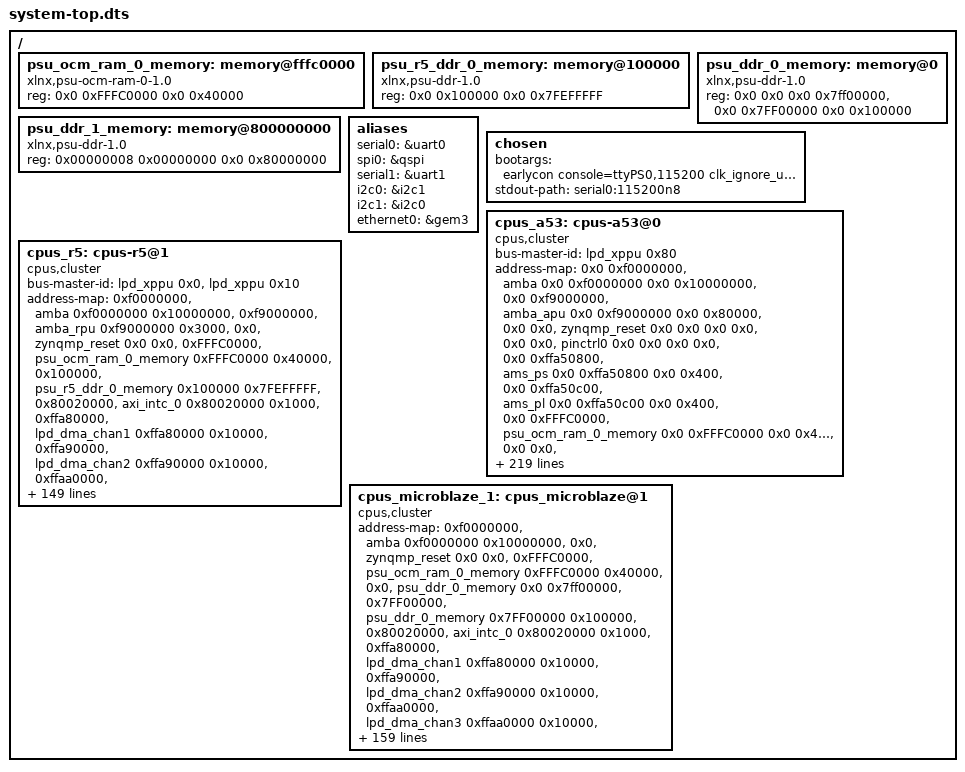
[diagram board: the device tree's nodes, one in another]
/dts-v1/;
#include "zynqmp.dtsi"
#include "zynqmp-clk-ccf.dtsi"
#include "zcu102-rev1.0.dtsi"
#include "pl.dtsi"
#include "pcw.dtsi"
/ {
	psu_ocm_ram_0_memory: memory@fffc0000 {
		compatible = "xlnx,psu-ocm-ram-0-1.0" , "mmio-sram";
		device_type = "memory";
		reg = <0x0 0xFFFC0000 0x0 0x40000>;
	};
	psu_r5_ddr_0_memory: memory@100000 {
		compatible = "xlnx,psu-ddr-1.0";
		device_type = "memory";
		reg = <0x0 0x100000 0x0 0x7FEFFFFF>;
	};
	psu_ddr_0_memory: memory@0 {
		compatible = "xlnx,psu-ddr-1.0";
		device_type = "memory";
		reg = <0x0 0x0 0x0 0x7ff00000>, <0x0 0x7FF00000 0x0 0x100000>;
	};
	psu_ddr_1_memory: memory@800000000 {
		compatible = "xlnx,psu-ddr-1.0";
		device_type = "memory";
		reg = <0x00000008 0x00000000 0x0 0x80000000>;
	};
	aliases {
		serial0 = &uart0;
		spi0 = &qspi;
		serial1 = &uart1;
		i2c0 = &i2c1;
		i2c1 = &i2c0;
		ethernet0 = &gem3;
	};
	chosen {
		bootargs = "earlycon console=ttyPS0,115200 clk_ignore_unused init_fatal_sh=1";
		stdout-path = "serial0:115200n8";
	};
	cpus_a53: cpus-a53@0 {
		compatible = "cpus,cluster";
		bus-master-id = <&lpd_xppu 0x80>;
		address-map = <0x0 0xf0000000 &amba 0x0 0xf0000000 0x0 0x10000000>, 
			      <0x0 0xf9000000 &amba_apu 0x0 0xf9000000 0x0 0x80000>, 
			      <0x0 0x0 &zynqmp_reset 0x0 0x0 0x0 0x0>, 
			      <0x0 0x0 &pinctrl0 0x0 0x0 0x0 0x0>, 
			      <0x0 0xffa50800 &ams_ps 0x0 0xffa50800 0x0 0x400>, 
			      <0x0 0xffa50c00 &ams_pl 0x0 0xffa50c00 0x0 0x400>, 
			      <0x0 0xFFFC0000 &psu_ocm_ram_0_memory 0x0 0xFFFC0000 0x0 0x40000>, 
			      <0x0 0x0 &psu_ddr_0_memory 0x0 0x0 0x0 0x7ff00000>, 
			      <0x00000008 0x00000000 &psu_ddr_1_memory 0x00000008 0x00000000 0x0 0x80000000>, 
			      <0x0 0x80020000 &axi_intc_0 0x0 0x80020000 0x0 0x1000>, 
			      <0x0 0xf9010000 &gic_a53 0x0 0xf9010000 0x0 0x70000>, 
			      <0x0 0xffa80000 &lpd_dma_chan1 0x0 0xffa80000 0x0 0x10000>, 
			      <0x0 0xffa90000 &lpd_dma_chan2 0x0 0xffa90000 0x0 0x10000>, 
			      <0x0 0xffaa0000 &lpd_dma_chan3 0x0 0xffaa0000 0x0 0x10000>, 
			      <0x0 0xffab0000 &lpd_dma_chan4 0x0 0xffab0000 0x0 0x10000>, 
			      <0x0 0xffac0000 &lpd_dma_chan5 0x0 0xffac0000 0x0 0x10000>, 
			      <0x0 0xffad0000 &lpd_dma_chan6 0x0 0xffad0000 0x0 0x10000>, 
			      <0x0 0xffae0000 &lpd_dma_chan7 0x0 0xffae0000 0x0 0x10000>, 
			      <0x0 0xffaf0000 &lpd_dma_chan8 0x0 0xffaf0000 0x0 0x10000>, 
			      <0x0 0xfd360000 &psu_afi_0 0x0 0xfd360000 0x0 0x10000>, 
			      <0x0 0xfd370000 &psu_afi_1 0x0 0xfd370000 0x0 0x10000>, 
			      <0x0 0xfd380000 &psu_afi_2 0x0 0xfd380000 0x0 0x10000>, 
			      <0x0 0xfd390000 &psu_afi_3 0x0 0xfd390000 0x0 0x10000>, 
			      <0x0 0xfd3a0000 &psu_afi_4 0x0 0xfd3a0000 0x0 0x10000>, 
			      <0x0 0xfd3b0000 &psu_afi_5 0x0 0xfd3b0000 0x0 0x10000>, 
			      <0x0 0xff9b0000 &psu_afi_6 0x0 0xff9b0000 0x0 0x10000>, 
			      <0x0 0xffa50000 &xilinx_ams 0x0 0xffa50000 0x0 0x10000>, 
			      <0x0 0xfd0b0000 &perf_monitor_ddr 0x0 0xfd0b0000 0x0 0x10000>, 
			      <0x0 0xffa00000 &perf_monitor_ocm 0x0 0xffa00000 0x0 0x10000>, 
			      <0x0 0xffa10000 &perf_monitor_lpd 0x0 0xffa10000 0x0 0x10000>, 
			      <0x0 0xfd490000 &perf_monitor_cci 0x0 0xfd490000 0x0 0x10000>, 
			      <0x0 0xfd5c0000 &psu_apu 0x0 0xfd5c0000 0x0 0x10000>, 
			      <0x0 0xff070000 &can1 0x0 0xff070000 0x0 0x10000>, 
			      <0x0 0xfd6e0000 &psu_cci_gpv 0x0 0xfd6e0000 0x0 0x10000>, 
			      <0x0 0xfd5e0000 &psu_cci_reg 0x0 0xfd5e0000 0x0 0x10000>, 
			      <0x0 0xfe800000 &coresight_0 0x0 0xfe800000 0x0 0x800000>, 
			      <0x0 0xfd1a0000 &psu_crf_apb 0x0 0xfd1a0000 0x0 0x140000>, 
			      <0x0 0xff5e0000 &psu_crl_apb 0x0 0xff5e0000 0x0 0x280000>, 
			      <0x0 0xffca0000 &psu_csu_0 0x0 0xffca0000 0x0 0x10000>, 
			      <0x0 0xffc80000 &csudma_0 0x0 0xffc80000 0x0 0x20000>, 
			      <0x0 0xff380000 &psu_ctrl_ipi 0x0 0xff380000 0x0 0x80000>, 
			      <0x0 0xfd080000 &psu_ddr_phy 0x0 0xfd080000 0x0 0x10000>, 
			      <0x0 0xfd090000 &psu_ddr_qos_ctrl 0x0 0xfd090000 0x0 0x10000>, 
			      <0x0 0xfd000000 &psu_ddr_xmpu0_cfg 0x0 0xfd000000 0x0 0x10000>, 
			      <0x0 0xfd010000 &psu_ddr_xmpu1_cfg 0x0 0xfd010000 0x0 0x10000>, 
			      <0x0 0xfd020000 &psu_ddr_xmpu2_cfg 0x0 0xfd020000 0x0 0x10000>, 
			      <0x0 0xfd030000 &psu_ddr_xmpu3_cfg 0x0 0xfd030000 0x0 0x10000>, 
			      <0x0 0xfd040000 &psu_ddr_xmpu4_cfg 0x0 0xfd040000 0x0 0x10000>, 
			      <0x0 0xfd050000 &psu_ddr_xmpu5_cfg 0x0 0xfd050000 0x0 0x10000>, 
			      <0x0 0xfd070000 &mc 0x0 0xfd070000 0x0 0x1000>, 
			      <0x0 0xfd4a0000 &zynqmp_dpsub 0x0 0xfd4a0000 0x0 0x10000>, 
			      <0x0 0xfd4c0000 &zynqmp_dpdma 0x0 0xfd4c0000 0x0 0x10000>, 
			      <0x0 0xffcc0000 &psu_efuse 0x0 0xffcc0000 0x0 0x10000>, 
			      <0x0 0xff0e0000 &gem3 0x0 0xff0e0000 0x0 0x10000>, 
			      <0x0 0xfd700000 &psu_fpd_gpv 0x0 0xfd700000 0x0 0x100000>, 
			      <0x0 0xfd610000 &psu_fpd_slcr 0x0 0xfd610000 0x0 0x80000>, 
			      <0x0 0xfd690000 &psu_fpd_slcr_secure 0x0 0xfd690000 0x0 0x40000>, 
			      <0x0 0xfd5d0000 &psu_fpd_xmpu_cfg 0x0 0xfd5d0000 0x0 0x10000>, 
			      <0x0 0xfd4f0000 &psu_fpd_xmpu_sink 0x0 0xfd4f0000 0x0 0x10000>, 
			      <0x0 0xfd500000 &fpd_dma_chan1 0x0 0xfd500000 0x0 0x10000>, 
			      <0x0 0xfd510000 &fpd_dma_chan2 0x0 0xfd510000 0x0 0x10000>, 
			      <0x0 0xfd520000 &fpd_dma_chan3 0x0 0xfd520000 0x0 0x10000>, 
			      <0x0 0xfd530000 &fpd_dma_chan4 0x0 0xfd530000 0x0 0x10000>, 
			      <0x0 0xfd540000 &fpd_dma_chan5 0x0 0xfd540000 0x0 0x10000>, 
			      <0x0 0xfd550000 &fpd_dma_chan6 0x0 0xfd550000 0x0 0x10000>, 
			      <0x0 0xfd560000 &fpd_dma_chan7 0x0 0xfd560000 0x0 0x10000>, 
			      <0x0 0xfd570000 &fpd_dma_chan8 0x0 0xfd570000 0x0 0x10000>, 
			      <0x0 0xff0a0000 &gpio 0x0 0xff0a0000 0x0 0x10000>, 
			      <0x0 0xfd4b0000 &gpu 0x0 0xfd4b0000 0x0 0x10000>, 
			      <0x0 0xff020000 &i2c0 0x0 0xff020000 0x0 0x10000>, 
			      <0x0 0xff030000 &i2c1 0x0 0xff030000 0x0 0x10000>, 
			      <0x0 0xff250000 &psu_iou_scntr 0x0 0xff250000 0x0 0x10000>, 
			      <0x0 0xff260000 &psu_iou_scntrs 0x0 0xff260000 0x0 0x10000>, 
			      <0x0 0xff240000 &psu_iousecure_slcr 0x0 0xff240000 0x0 0x10000>, 
			      <0x0 0xff180000 &psu_iouslcr_0 0x0 0xff180000 0x0 0xc0000>, 
			      <0x0 0xff300000 &ipi0 0x0 0xff300000 0x0 0x10000>, 
			      <0x0 0xff410000 &psu_lpd_slcr 0x0 0xff410000 0x0 0xa0000>, 
			      <0x0 0xff4b0000 &psu_lpd_slcr_secure 0x0 0xff4b0000 0x0 0x30000>, 
			      <0x0 0xff980000 &lpd_xppu 0x0 0xff980000 0x0 0x10000>, 
			      <0x0 0xff9c0000 &psu_lpd_xppu_sink 0x0 0xff9c0000 0x0 0x10000>, 
			      <0x0 0xffcf0000 &psu_mbistjtag 0x0 0xffcf0000 0x0 0x10000>, 
			      <0x0 0xff990000 &psu_message_buffers 0x0 0xff990000 0x0 0x10000>, 
			      <0x0 0xff960000 &ocm 0x0 0xff960000 0x0 0x10000>, 
			      <0x0 0xffa70000 &psu_ocm_xmpu_cfg 0x0 0xffa70000 0x0 0x10000>, 
			      <0x0 0xfd0e0000 &pcie 0x0 0xfd0e0000 0x0 0x10000>, 
			      <0x0 0xfd480000 &psu_pcie_attrib_0 0x0 0xfd480000 0x0 0x10000>, 
			      <0x0 0xfd0f0000 &psu_pcie_dma 0x0 0xfd0f0000 0x0 0x10000>, 
			      <0x00000006 0x00000000 &psu_pcie_high1 0x00000006 0x00000000 0x00000002 0x00000000>, 
			      <0x00000080 0x00000000 &psu_pcie_high2 0x00000080 0x00000000 0x00000040 0x00000000>, 
			      <0x0 0xe0000000 &psu_pcie_low 0x0 0xe0000000 0x0 0x10000000>, 
			      <0x0 0xffd80000 &psu_pmu_global_0 0x0 0xffd80000 0x0 0x40000>, 
			      <0x0 0xff0f0000 &qspi 0x0 0xff0f0000 0x0 0x10000>, 
			      <0x0 0xc0000000 &psu_qspi_linear_0 0x0 0xc0000000 0x0 0x20000000>, 
			      <0x0 0xffe00000 &psu_r5_0_atcm_global 0x0 0xffe00000 0x0 0x10000>, 
			      <0x0 0xffe20000 &psu_r5_0_btcm_global 0x0 0xffe20000 0x0 0x10000>, 
			      <0x0 0xffe90000 &psu_r5_1_atcm_global 0x0 0xffe90000 0x0 0x10000>, 
			      <0x0 0xffeb0000 &psu_r5_1_btcm_global 0x0 0xffeb0000 0x0 0x10000>, 
			      <0x0 0xffe00000 &psu_r5_tcm_ram_global 0x0 0xffe00000 0x0 0x40000>, 
			      <0x0 0xff9a0000 &psu_rpu 0x0 0xff9a0000 0x0 0x10000>, 
			      <0x0 0xffce0000 &psu_rsa 0x0 0xffce0000 0x0 0x10000>, 
			      <0x0 0xffa60000 &rtc 0x0 0xffa60000 0x0 0x10000>, 
			      <0x0 0xfd0c0000 &sata 0x0 0xfd0c0000 0x0 0x10000>, 
			      <0x0 0xff170000 &sdhci1 0x0 0xff170000 0x0 0x10000>, 
			      <0x0 0xfd400000 &psgtr 0x0 0xfd400000 0x0 0x80000>, 
			      <0x0 0xfd3d0000 &psu_siou 0x0 0xfd3d0000 0x0 0x10000>, 
			      <0x0 0xfd800000 &smmu 0x0 0xfd800000 0x0 0x800000>, 
			      <0x0 0xfd5f0000 &psu_smmu_reg 0x0 0xfd5f0000 0x0 0x10000>, 
			      <0x0 0xff110000 &ttc0 0x0 0xff110000 0x0 0x10000>, 
			      <0x0 0xff120000 &ttc1 0x0 0xff120000 0x0 0x10000>, 
			      <0x0 0xff130000 &ttc2 0x0 0xff130000 0x0 0x10000>, 
			      <0x0 0xff140000 &ttc3 0x0 0xff140000 0x0 0x10000>, 
			      <0x0 0xff000000 &uart0 0x0 0xff000000 0x0 0x10000>, 
			      <0x0 0xff010000 &uart1 0x0 0xff010000 0x0 0x10000>, 
			      <0x0 0xff9d0000 &usb0 0x0 0xff9d0000 0x0 0x10000>, 
			      <0x0 0xfe200000 &dwc3_0 0x0 0xfe200000 0x0 0x100000>, 
			      <0x0 0xff150000 &lpd_watchdog 0x0 0xff150000 0x0 0x10000>, 
			      <0x0 0xfd4d0000 &watchdog0 0x0 0xfd4d0000 0x0 0x10000>;
		#ranges-address-cells = <0x2>;
		#ranges-size-cells = <0x2>;
	};
	cpus_r5: cpus-r5@1 {
		compatible = "cpus,cluster";
		bus-master-id = <&lpd_xppu 0x0> , <&lpd_xppu 0x10>;
		address-map = <0xf0000000 &amba 0xf0000000 0x10000000>, 
			      <0xf9000000 &amba_rpu 0xf9000000 0x3000>, 
			      <0x0 &zynqmp_reset 0x0 0x0>, 
			      <0xFFFC0000 &psu_ocm_ram_0_memory 0xFFFC0000 0x40000>, 
			      <0x100000 &psu_r5_ddr_0_memory 0x100000 0x7FEFFFFF>, 
			      <0x80020000 &axi_intc_0 0x80020000 0x1000>, 
			      <0xffa80000 &lpd_dma_chan1 0xffa80000 0x10000>, 
			      <0xffa90000 &lpd_dma_chan2 0xffa90000 0x10000>, 
			      <0xffaa0000 &lpd_dma_chan3 0xffaa0000 0x10000>, 
			      <0xffab0000 &lpd_dma_chan4 0xffab0000 0x10000>, 
			      <0xffac0000 &lpd_dma_chan5 0xffac0000 0x10000>, 
			      <0xffad0000 &lpd_dma_chan6 0xffad0000 0x10000>, 
			      <0xffae0000 &lpd_dma_chan7 0xffae0000 0x10000>, 
			      <0xffaf0000 &lpd_dma_chan8 0xffaf0000 0x10000>, 
			      <0xfd360000 &psu_afi_0 0xfd360000 0x10000>, 
			      <0xfd370000 &psu_afi_1 0xfd370000 0x10000>, 
			      <0xfd380000 &psu_afi_2 0xfd380000 0x10000>, 
			      <0xfd390000 &psu_afi_3 0xfd390000 0x10000>, 
			      <0xfd3a0000 &psu_afi_4 0xfd3a0000 0x10000>, 
			      <0xfd3b0000 &psu_afi_5 0xfd3b0000 0x10000>, 
			      <0xff9b0000 &psu_afi_6 0xff9b0000 0x10000>, 
			      <0xffa50000 &xilinx_ams 0xffa50000 0x10000>, 
			      <0xfd0b0000 &perf_monitor_ddr 0xfd0b0000 0x10000>, 
			      <0xffa00000 &perf_monitor_ocm 0xffa00000 0x10000>, 
			      <0xffa10000 &perf_monitor_lpd 0xffa10000 0x10000>, 
			      <0xfd490000 &perf_monitor_cci 0xfd490000 0x10000>, 
			      <0xfd5c0000 &psu_apu 0xfd5c0000 0x10000>, 
			      <0xff070000 &can1 0xff070000 0x10000>, 
			      <0xfd6e0000 &psu_cci_gpv 0xfd6e0000 0x10000>, 
			      <0xfd5e0000 &psu_cci_reg 0xfd5e0000 0x10000>, 
			      <0xfe800000 &coresight_0 0xfe800000 0x800000>, 
			      <0xfd1a0000 &psu_crf_apb 0xfd1a0000 0x140000>, 
			      <0xff5e0000 &psu_crl_apb 0xff5e0000 0x280000>, 
			      <0xffca0000 &psu_csu_0 0xffca0000 0x10000>, 
			      <0xffc80000 &csudma_0 0xffc80000 0x20000>, 
			      <0xff380000 &psu_ctrl_ipi 0xff380000 0x80000>, 
			      <0xfd080000 &psu_ddr_phy 0xfd080000 0x10000>, 
			      <0xfd090000 &psu_ddr_qos_ctrl 0xfd090000 0x10000>, 
			      <0xfd000000 &psu_ddr_xmpu0_cfg 0xfd000000 0x10000>, 
			      <0xfd010000 &psu_ddr_xmpu1_cfg 0xfd010000 0x10000>, 
			      <0xfd020000 &psu_ddr_xmpu2_cfg 0xfd020000 0x10000>, 
			      <0xfd030000 &psu_ddr_xmpu3_cfg 0xfd030000 0x10000>, 
			      <0xfd040000 &psu_ddr_xmpu4_cfg 0xfd040000 0x10000>, 
			      <0xfd050000 &psu_ddr_xmpu5_cfg 0xfd050000 0x10000>, 
			      <0xfd070000 &mc 0xfd070000 0x1000>, 
			      <0xfd4a0000 &zynqmp_dpsub 0xfd4a0000 0x10000>, 
			      <0xfd4c0000 &zynqmp_dpdma 0xfd4c0000 0x10000>, 
			      <0xffcc0000 &psu_efuse 0xffcc0000 0x10000>, 
			      <0xff0e0000 &gem3 0xff0e0000 0x10000>, 
			      <0xfd700000 &psu_fpd_gpv 0xfd700000 0x100000>, 
			      <0xfd610000 &psu_fpd_slcr 0xfd610000 0x80000>, 
			      <0xfd690000 &psu_fpd_slcr_secure 0xfd690000 0x40000>, 
			      <0xfd5d0000 &psu_fpd_xmpu_cfg 0xfd5d0000 0x10000>, 
			      <0xfd4f0000 &psu_fpd_xmpu_sink 0xfd4f0000 0x10000>, 
			      <0xfd500000 &fpd_dma_chan1 0xfd500000 0x10000>, 
			      <0xfd510000 &fpd_dma_chan2 0xfd510000 0x10000>, 
			      <0xfd520000 &fpd_dma_chan3 0xfd520000 0x10000>, 
			      <0xfd530000 &fpd_dma_chan4 0xfd530000 0x10000>, 
			      <0xfd540000 &fpd_dma_chan5 0xfd540000 0x10000>, 
			      <0xfd550000 &fpd_dma_chan6 0xfd550000 0x10000>, 
			      <0xfd560000 &fpd_dma_chan7 0xfd560000 0x10000>, 
			      <0xfd570000 &fpd_dma_chan8 0xfd570000 0x10000>, 
			      <0xff0a0000 &gpio 0xff0a0000 0x10000>, 
			      <0xfd4b0000 &gpu 0xfd4b0000 0x10000>, 
			      <0xff020000 &i2c0 0xff020000 0x10000>, 
			      <0xff030000 &i2c1 0xff030000 0x10000>, 
			      <0xff250000 &psu_iou_scntr 0xff250000 0x10000>, 
			      <0xff260000 &psu_iou_scntrs 0xff260000 0x10000>, 
			      <0xff240000 &psu_iousecure_slcr 0xff240000 0x10000>, 
			      <0xff180000 &psu_iouslcr_0 0xff180000 0xc0000>, 
			      <0xff410000 &psu_lpd_slcr 0xff410000 0xa0000>, 
			      <0xff4b0000 &psu_lpd_slcr_secure 0xff4b0000 0x30000>, 
			      <0xff980000 &lpd_xppu 0xff980000 0x10000>, 
			      <0xff9c0000 &psu_lpd_xppu_sink 0xff9c0000 0x10000>, 
			      <0xffcf0000 &psu_mbistjtag 0xffcf0000 0x10000>, 
			      <0xff990000 &psu_message_buffers 0xff990000 0x10000>, 
			      <0xff960000 &ocm 0xff960000 0x10000>, 
			      <0xffa70000 &psu_ocm_xmpu_cfg 0xffa70000 0x10000>, 
			      <0xfd0e0000 &pcie 0xfd0e0000 0x10000>, 
			      <0xfd480000 &psu_pcie_attrib_0 0xfd480000 0x10000>, 
			      <0xfd0f0000 &psu_pcie_dma 0xfd0f0000 0x10000>, 
			      <0x00000000 &psu_pcie_high1 0x00000000 0x00000000>, 
			      <0x00000000 &psu_pcie_high2 0x00000000 0x00000000>, 
			      <0xe0000000 &psu_pcie_low 0xe0000000 0x10000000>, 
			      <0xffd80000 &psu_pmu_global_0 0xffd80000 0x40000>, 
			      <0xff0f0000 &qspi 0xff0f0000 0x10000>, 
			      <0xc0000000 &psu_qspi_linear_0 0xc0000000 0x20000000>, 
			      <0xff9a0000 &psu_rpu 0xff9a0000 0x10000>, 
			      <0xffce0000 &psu_rsa 0xffce0000 0x10000>, 
			      <0xffa60000 &rtc 0xffa60000 0x10000>, 
			      <0xfd0c0000 &sata 0xfd0c0000 0x10000>, 
			      <0xff170000 &sdhci1 0xff170000 0x10000>, 
			      <0xfd400000 &psgtr 0xfd400000 0x80000>, 
			      <0xfd3d0000 &psu_siou 0xfd3d0000 0x10000>, 
			      <0xfd800000 &smmu 0xfd800000 0x800000>, 
			      <0xfd5f0000 &psu_smmu_reg 0xfd5f0000 0x10000>, 
			      <0xff110000 &ttc0 0xff110000 0x10000>, 
			      <0xff120000 &ttc1 0xff120000 0x10000>, 
			      <0xff130000 &ttc2 0xff130000 0x10000>, 
			      <0xff140000 &ttc3 0xff140000 0x10000>, 
			      <0xff000000 &uart0 0xff000000 0x10000>, 
			      <0xff010000 &uart1 0xff010000 0x10000>, 
			      <0xff9d0000 &usb0 0xff9d0000 0x10000>, 
			      <0xfe200000 &dwc3_0 0xfe200000 0x100000>, 
			      <0xff150000 &lpd_watchdog 0xff150000 0x10000>, 
			      <0xfd4d0000 &watchdog0 0xfd4d0000 0x10000>, 
			      <0xffcb0000 &csuwdt_0 0xffcb0000 0x10000>, 
			      <0xff310000 &ipi1 0xff310000 0x10000>, 
			      <0x0 &psu_r5_0_atcm 0x0 0x10000>, 
			      <0x20000 &psu_r5_0_btcm 0x20000 0x10000>, 
			      <0x0 &psu_r5_tcm_ram_0 0x0 0x40000>, 
			      <0xf9000000 &gic_r5 0xf9000000 0x10000>, 
			      <0xff320000 &ipi2 0xff320000 0x10000>, 
			      <0x0 &psu_r5_1_atcm 0x0 0x10000>, 
			      <0x20000 &psu_r5_1_btcm 0x20000 0x10000>;
		#ranges-address-cells = <0x1>;
		#ranges-size-cells = <0x1>;
	};
	cpus_microblaze_1: cpus_microblaze@1 {
		compatible = "cpus,cluster";
		address-map = <0xf0000000 &amba 0xf0000000 0x10000000>, 
			      <0x0 &zynqmp_reset 0x0 0x0>, 
			      <0xFFFC0000 &psu_ocm_ram_0_memory 0xFFFC0000 0x40000>, 
			      <0x0 &psu_ddr_0_memory 0x0 0x7ff00000>, 
			      <0x7FF00000 &psu_ddr_0_memory 0x7FF00000 0x100000>, 
			      <0x80020000 &axi_intc_0 0x80020000 0x1000>, 
			      <0xffa80000 &lpd_dma_chan1 0xffa80000 0x10000>, 
			      <0xffa90000 &lpd_dma_chan2 0xffa90000 0x10000>, 
			      <0xffaa0000 &lpd_dma_chan3 0xffaa0000 0x10000>, 
			      <0xffab0000 &lpd_dma_chan4 0xffab0000 0x10000>, 
			      <0xffac0000 &lpd_dma_chan5 0xffac0000 0x10000>, 
			      <0xffad0000 &lpd_dma_chan6 0xffad0000 0x10000>, 
			      <0xffae0000 &lpd_dma_chan7 0xffae0000 0x10000>, 
			      <0xffaf0000 &lpd_dma_chan8 0xffaf0000 0x10000>, 
			      <0xfd360000 &psu_afi_0 0xfd360000 0x10000>, 
			      <0xfd370000 &psu_afi_1 0xfd370000 0x10000>, 
			      <0xfd380000 &psu_afi_2 0xfd380000 0x10000>, 
			      <0xfd390000 &psu_afi_3 0xfd390000 0x10000>, 
			      <0xfd3a0000 &psu_afi_4 0xfd3a0000 0x10000>, 
			      <0xfd3b0000 &psu_afi_5 0xfd3b0000 0x10000>, 
			      <0xff9b0000 &psu_afi_6 0xff9b0000 0x10000>, 
			      <0xffa50000 &xilinx_ams 0xffa50000 0x10000>, 
			      <0xfd0b0000 &perf_monitor_ddr 0xfd0b0000 0x10000>, 
			      <0xffa00000 &perf_monitor_ocm 0xffa00000 0x10000>, 
			      <0xffa10000 &perf_monitor_lpd 0xffa10000 0x10000>, 
			      <0xfd490000 &perf_monitor_cci 0xfd490000 0x10000>, 
			      <0xfd5c0000 &psu_apu 0xfd5c0000 0x10000>, 
			      <0xff070000 &can1 0xff070000 0x10000>, 
			      <0xfd6e0000 &psu_cci_gpv 0xfd6e0000 0x10000>, 
			      <0xfd5e0000 &psu_cci_reg 0xfd5e0000 0x10000>, 
			      <0xfd1a0000 &psu_crf_apb 0xfd1a0000 0x140000>, 
			      <0xff5e0000 &psu_crl_apb 0xff5e0000 0x280000>, 
			      <0xffca0000 &psu_csu_0 0xffca0000 0x10000>, 
			      <0xffc80000 &csudma_0 0xffc80000 0x20000>, 
			      <0xff380000 &psu_ctrl_ipi 0xff380000 0x80000>, 
			      <0xfd080000 &psu_ddr_phy 0xfd080000 0x10000>, 
			      <0xfd090000 &psu_ddr_qos_ctrl 0xfd090000 0x10000>, 
			      <0xfd000000 &psu_ddr_xmpu0_cfg 0xfd000000 0x10000>, 
			      <0xfd010000 &psu_ddr_xmpu1_cfg 0xfd010000 0x10000>, 
			      <0xfd020000 &psu_ddr_xmpu2_cfg 0xfd020000 0x10000>, 
			      <0xfd030000 &psu_ddr_xmpu3_cfg 0xfd030000 0x10000>, 
			      <0xfd040000 &psu_ddr_xmpu4_cfg 0xfd040000 0x10000>, 
			      <0xfd050000 &psu_ddr_xmpu5_cfg 0xfd050000 0x10000>, 
			      <0xfd070000 &mc 0xfd070000 0x1000>, 
			      <0xfd4a0000 &zynqmp_dpsub 0xfd4a0000 0x10000>, 
			      <0xfd4c0000 &zynqmp_dpdma 0xfd4c0000 0x10000>, 
			      <0xffcc0000 &psu_efuse 0xffcc0000 0x10000>, 
			      <0xff0e0000 &gem3 0xff0e0000 0x10000>, 
			      <0xfd700000 &psu_fpd_gpv 0xfd700000 0x100000>, 
			      <0xfd610000 &psu_fpd_slcr 0xfd610000 0x80000>, 
			      <0xfd690000 &psu_fpd_slcr_secure 0xfd690000 0x40000>, 
			      <0xfd5d0000 &psu_fpd_xmpu_cfg 0xfd5d0000 0x10000>, 
			      <0xfd4f0000 &psu_fpd_xmpu_sink 0xfd4f0000 0x10000>, 
			      <0xfd500000 &fpd_dma_chan1 0xfd500000 0x10000>, 
			      <0xfd510000 &fpd_dma_chan2 0xfd510000 0x10000>, 
			      <0xfd520000 &fpd_dma_chan3 0xfd520000 0x10000>, 
			      <0xfd530000 &fpd_dma_chan4 0xfd530000 0x10000>, 
			      <0xfd540000 &fpd_dma_chan5 0xfd540000 0x10000>, 
			      <0xfd550000 &fpd_dma_chan6 0xfd550000 0x10000>, 
			      <0xfd560000 &fpd_dma_chan7 0xfd560000 0x10000>, 
			      <0xfd570000 &fpd_dma_chan8 0xfd570000 0x10000>, 
			      <0xff0a0000 &gpio 0xff0a0000 0x10000>, 
			      <0xfd4b0000 &gpu 0xfd4b0000 0x10000>, 
			      <0xff020000 &i2c0 0xff020000 0x10000>, 
			      <0xff030000 &i2c1 0xff030000 0x10000>, 
			      <0xff250000 &psu_iou_scntr 0xff250000 0x10000>, 
			      <0xff260000 &psu_iou_scntrs 0xff260000 0x10000>, 
			      <0xff240000 &psu_iousecure_slcr 0xff240000 0x10000>, 
			      <0xff180000 &psu_iouslcr_0 0xff180000 0xc0000>, 
			      <0xff410000 &psu_lpd_slcr 0xff410000 0xa0000>, 
			      <0xff4b0000 &psu_lpd_slcr_secure 0xff4b0000 0x30000>, 
			      <0xff980000 &lpd_xppu 0xff980000 0x10000>, 
			      <0xff9c0000 &psu_lpd_xppu_sink 0xff9c0000 0x10000>, 
			      <0xffcf0000 &psu_mbistjtag 0xffcf0000 0x10000>, 
			      <0xff990000 &psu_message_buffers 0xff990000 0x10000>, 
			      <0xff960000 &ocm 0xff960000 0x10000>, 
			      <0xffa70000 &psu_ocm_xmpu_cfg 0xffa70000 0x10000>, 
			      <0xfd0e0000 &pcie 0xfd0e0000 0x10000>, 
			      <0xfd480000 &psu_pcie_attrib_0 0xfd480000 0x10000>, 
			      <0xfd0f0000 &psu_pcie_dma 0xfd0f0000 0x10000>, 
			      <0x00000000 &psu_pcie_high1 0x00000000 0x00000000>, 
			      <0x00000000 &psu_pcie_high2 0x00000000 0x00000000>, 
			      <0xe0000000 &psu_pcie_low 0xe0000000 0x10000000>, 
			      <0xffd80000 &psu_pmu_global_0 0xffd80000 0x40000>, 
			      <0xff0f0000 &qspi 0xff0f0000 0x10000>, 
			      <0xc0000000 &psu_qspi_linear_0 0xc0000000 0x20000000>, 
			      <0xffe00000 &psu_r5_0_atcm_global 0xffe00000 0x10000>, 
			      <0xffe20000 &psu_r5_0_btcm_global 0xffe20000 0x10000>, 
			      <0xffe90000 &psu_r5_1_atcm_global 0xffe90000 0x10000>, 
			      <0xffeb0000 &psu_r5_1_btcm_global 0xffeb0000 0x10000>, 
			      <0xffe00000 &psu_r5_tcm_ram_global 0xffe00000 0x40000>, 
			      <0xff9a0000 &psu_rpu 0xff9a0000 0x10000>, 
			      <0xffce0000 &psu_rsa 0xffce0000 0x10000>, 
			      <0xffa60000 &rtc 0xffa60000 0x10000>, 
			      <0xfd0c0000 &sata 0xfd0c0000 0x10000>, 
			      <0xff170000 &sdhci1 0xff170000 0x10000>, 
			      <0xfd400000 &psgtr 0xfd400000 0x80000>, 
			      <0xfd3d0000 &psu_siou 0xfd3d0000 0x10000>, 
			      <0xfd800000 &smmu 0xfd800000 0x800000>, 
			      <0xfd5f0000 &psu_smmu_reg 0xfd5f0000 0x10000>, 
			      <0xff110000 &ttc0 0xff110000 0x10000>, 
			      <0xff120000 &ttc1 0xff120000 0x10000>, 
			      <0xff130000 &ttc2 0xff130000 0x10000>, 
			      <0xff140000 &ttc3 0xff140000 0x10000>, 
			      <0xff000000 &uart0 0xff000000 0x10000>, 
			      <0xff010000 &uart1 0xff010000 0x10000>, 
			      <0xff9d0000 &usb0 0xff9d0000 0x10000>, 
			      <0xfe200000 &dwc3_0 0xfe200000 0x100000>, 
			      <0xff150000 &lpd_watchdog 0xff150000 0x10000>, 
			      <0xfd4d0000 &watchdog0 0xfd4d0000 0x10000>, 
			      <0xffcb0000 &csuwdt_0 0xffcb0000 0x10000>, 
			      <0xffcd0000 &psu_bbram_0 0xffcd0000 0x10000>, 
			      <0xff330000 &ipi3 0xff330000 0x1000>, 
			      <0xff331000 &ipi4 0xff331000 0x1000>, 
			      <0xff332000 &ipi5 0xff332000 0x1000>, 
			      <0xff333000 &ipi6 0xff333000 0x1000>, 
			      <0xffd40000 &psu_pmu_iomodule 0xffd40000 0x20000>, 
			      <0xffdc0000 &psu_pmu_ram 0xffdc0000 0x20000>, 
			      <0xffdc0000 &psu_pmu_ram 0xffdc0000 0x20000>;
		bus-master-id = <&lpd_xppu 0x40>;
		#ranges-address-cells = <0x1>;
		#ranges-size-cells = <0x1>;
	};
};
